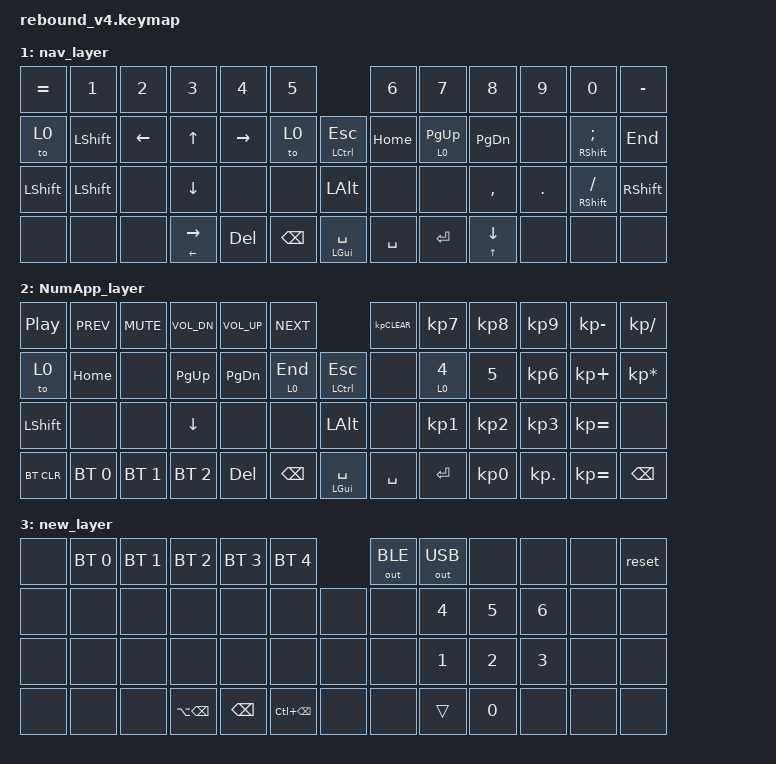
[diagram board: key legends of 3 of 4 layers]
/*
 * Copyright (c) 2023 The ZMK Contributors
 *
 * SPDX-License-Identifier: MIT
 */

#include <behaviors.dtsi>
#include <dt-bindings/zmk/keys.h>
#include <dt-bindings/zmk/bt.h>
#include <dt-bindings/zmk/modifiers.h>
#include <dt-bindings/zmk/outputs.h>

/ {
    behaviors {
        hm: homerow_mods {
            compatible = "zmk,behavior-hold-tap";
            label = "HOMEROW_MODS";
            #binding-cells = <2>;
            tapping_term_ms = <100>;
            flavor = "tap-preferred";
            bindings = <&kp>, <&kp>;
        };
    };
    behaviors {
        la: launch_apps {
            compatible = "zmk,behavior-hold-tap";
            label = "LAUNCH_APPS";
            #binding-cells = <2>;
            tapping_term_ms = <400>;
            flavor = "tap-preferred";
            bindings = <&kp>, <&kp>;
        };
    };
	behaviors {
        lk: layer_keytap {
            compatible = "zmk,behavior-hold-tap";
            label = "LAYER_KEYTAP";
            #binding-cells = <2>;
            tapping_term_ms = <175>;
            flavor = "tap-preferred";
            bindings = <&to>, <&kp>;
        };
    };
    keymap {
        compatible = "zmk,keymap";

        default_layer {
     
// -------------------------------------------------------------------------------				  ------------------------------------------------------------------------------
// | todos TAB   |contacts  Q | cal  W  | safari   E    | mail      | texts  T    |  -----------------------|  |   Y   notes  | excel  U  | word   I  | pdf O     |   P          |   \ | |
// |   CAPS      |  L1mo  A   |   S     |   L2to D      | L1to F    |    G        |  | CTRL ESC             |  |   H          |  L1to  J  |   L2to K  |   L       |  L1mo ;      |  '    |
// |   LSHIFT    |  Z LSHFT   |   X     |    C          |  V        |    B        |  | ALT screenshot       |  |   N          |    M      |    ,      |   .       |   / RSHIFT   | RSHIFT|
// |             |    `       |   \     |  LEFT/RIGHT   | BSPSC/DEL |  L1mo BSPACE|  |  | CMD SPACE            |   SPACE      |  ENTER    |  UP/DOWN  |   [       |   ]          |       |
// ----------------------------------------------------------------------------------------------------------------------------------------------------------------------------------
//                         					  
		bindings = <
   &la LG(LS(LA(KP_N7))) TAB  &la LG(LS(LA(KP_N2))) Q  &la LG(LS(LA(KP_N1))) W  &la LG(LS(LA(KP_N4))) E   &la LG(LS(LA(KP_N3))) R  &la LG(LS(LA(KP_N9))) T  &la LG(LS(LA(KP_N0))) Y   &la LG(LS(LA(KP_N6))) U  &la LG(LS(LA(KP_N5))) I  &la LG(LS(LA(KP_N8))) O   &kp P   &kp BSLH
   &kp CAPS     &lt 1 A       &kp S     &lk 2 D         &lk 1 F       &kp G        &hm LCTRL ESC              &kp H        &lk 1 J     &lt 2 K       &kp L      &lt 1 SEMI      &lt 1 SQT
   &kp LSHFT    &mt LSHFT Z   &kp X     &kp C           &kp V         &kp B        &hm LALT LG(LS(NUMBER_4))  &kp N        &kp M       &kp COMMA     &kp DOT    &mt RSHFT FSLH  &kp RSHFT  
   &none        &kp GRAVE     &kp BSLH  &hm LEFT RIGHT  &hm BSPC DEL  &lt 1 BSPC   &hm LGUI SPACE             &kp SPACE    &kp ENTER   &hm UP DOWN   &kp LBKT   &kp RBKT        &none   
                        >;
	
			sensor-bindings = <&inc_dec_kp C_VOL_UP C_VOL_DN>;
                };

        nav_layer {
// ---------------------------------------------------------------------------					-----------------------------------------------------------------------------
// |  =      |  1 !       |  2 @      |  3 #        |  4  $      |  5  %     |   -------------  |   6 ^         |   7  &     |   8 *     |   9 (   |     0 )       |   - _  |
// | to L0   |            |  LEFT     |  UP         |  RIGHT     |  to L0    |   | CTRL ESC  |  |   HOME        | L0to PG UP | PG DN     |         |   ; RSHIFT    |   END  |
// | LSHIFT  |  LSHFT     |           |  DOWN       |            |           |   | ALT       |  |               |            |   ,       |   .     |   / RSHIFT    | RSHIFT |
// |         |            |           |  LEFT/RIGHT |  DELETE    |  BSPACE   |   | CMD SPACE |  |  SPACE        |    ENTER   | UP/DOWN |           |               |        | 
// --------------------------------------------------------------------------------------------------------------------------------------------------------------------------
//
		bindings = < 
   &kp EQUAL  &kp N1      &kp N2       &kp N3          &kp N4      &kp N5                        &kp N6          &kp N7       &kp N8       &kp N9    &kp N0           &kp MINUS
   &to 0      &kp LSHFT   &kp LEFT     &kp UP          &kp RIGHT   &to 0         &hm LCTRL ESC   &kp HOME        &lk 0 PG_UP  &kp PG_DN    &none     &hm RSHFT SEMI   &kp END
   &kp LSHFT  &kp LSHFT   &none        &kp DOWN        &none       &none         &kp LALT        &none           &none        &kp COMMA    &kp DOT   &mt RSHFT FSLH   &kp RSHFT
   &none      &none       &none        &hm LEFT RIGHT  &kp DEL     &kp BSPC      &hm LGUI SPACE  &kp SPACE       &kp ENTER    &hm UP DOWN  &none     &none            &none
                        >;

			sensor-bindings = <&inc_dec_kp PG_DN PG_UP>;
                };

        NumApp_layer {
// ----------------------------------------------------------------------------					--------------------------------------------------------------------------------
// | PLY PAUSE| SKIP BK  |   MUTE     |   VOL DN    |  VOL UP     | SKIP FWD  | --------------  |      CLR       |     7      |     8     |     9    |     -      |     ÷      |
// |  L0to    |   HOME   |            |   PG UP     |  PG DN      | L0to END  | |  CTRL ESC   | |                |  L0to 4    |     5     |     6    |     +      |     *      |
// | LSHIFT   |          |            |   DOWN      |             |           | |  ALT        | |                |     1      |     2     |     3    |     =      |            |
// |BLUE T CLR| BT IPAD  | BT MAC     |  BT PHONE   |  DELETE     | BSPACE    | |  CMD SPACE  | |     SPACE      |    ENTER   |     0     |     .    |     =      |   BKSPC    |
// -----------------------------------------------------------------------------------------------------------------------------------------------------------------------------
//                                            
		bindings = <
   &kp C_PP    &kp C_PREV   &kp K_MUTE   &kp C_VOL_DN   &kp C_VOL_UP  &kp C_NEXT                    &kp KP_CLEAR     &kp KP_N7   &kp KP_N8   &kp KP_N9  &kp KP_MINUS  &kp KP_DIVIDE
   &to 0       &kp HOME     &none        &kp PG_UP      &kp PG_DN     &lk 0 END    &hm LCTRL ESC    &none            &lk 0 N4    &kp N5      &kp KP_N6  &kp KP_PLUS   &kp KP_MULTIPLY
   &kp LSHFT   &none        &none        &kp DOWN       &none         &none        &kp LALT         &none            &kp KP_N1   &kp KP_N2   &kp KP_N3  &kp KP_EQUAL  &none
   &bt BT_CLR  &bt BT_SEL 0 &bt BT_SEL 1 &bt BT_SEL 2   &kp DEL       &kp BSPC     &hm LGUI SPACE   &kp SPACE        &kp ENTER   &kp KP_N0   &kp KP_DOT &kp KP_EQUAL  &kp BSPC
                        >;

			sensor-bindings = <&inc_dec_kp RIGHT LEFT>;
                };

        new_layer {
// -----------------------------------------------------------------------------------------
// |         |     BT0    |    BT1     |    BT2      |    NUM           |       |           |       | NUM     |  7       |      8  |      9  |  -   |
// |   +     |     6      |     5      |     4       |     /            |       | |       | |       |      /  |       4  |      5  |      6  |   +  |
// |   =     |     3      |     2      |     1       |     *            |       | |       | |       |      *  |       1  |      2  |      3  |   =  |
// |   RET   |    .       |    0       |    0        |  CLR             |       | |       | |       |    CLR  |    0     |    0    |    .    |  RET | 
//                                            
		bindings = <
   &none     &bt BT_SEL 0  &bt BT_SEL 1 &bt BT_SEL 2 &bt BT_SEL 3  &bt BT_SEL 4             &out OUT_BLE  &out OUT_USB  &none     &none     &none     &reset   
   &none     &none         &none        &none        &none     &none         &none       &none  &kp N4    &kp N5     &kp N6    &none     &none
   &none     &none         &none        &none        &none     &none         &none       &none  &kp N1    &kp N2     &kp N3    &none     &none
   &none     &none         &none        &kp LA(BSPC) &kp BSPC&kp LC(BSPC) &none       &none  &trans    &kp N0     &none     &none     &none
                        >;

			sensor-bindings = <&inc_dec_kp RIGHT LEFT>;
                };
	};
};
